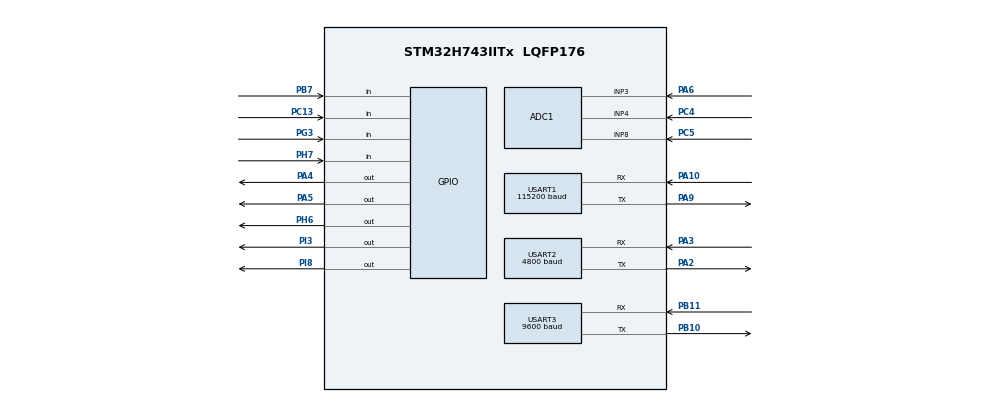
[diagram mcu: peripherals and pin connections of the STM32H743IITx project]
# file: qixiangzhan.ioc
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ADC1.Channel-8\#ChannelRegularConversion=ADC_CHANNEL_8
ADC1.ContinuousConvMode=DISABLE
ADC1.ConversionDataManagement=ADC_CONVERSIONDATA_DR
ADC1.EOCSelection=ADC_EOC_SINGLE_CONV
ADC1.NbrOfConversionFlag=1
ADC1.OffsetNumber-8\#ChannelRegularConversion=ADC_OFFSET_NONE
ADC1.OffsetSignedSaturation-8\#ChannelRegularConversion=DISABLE
ADC1.Overrun=ADC_OVR_DATA_PRESERVED
ADC1.Rank-8\#ChannelRegularConversion=1
ADC1.SamplingTime-8\#ChannelRegularConversion=ADC_SAMPLETIME_64CYCLES_5
ADC1.ScanConvMode=ADC_SCAN_DISABLE
ADC1.master=1
CORTEX_M7.default_mode_Activation=1
Dma.ADC1.0.Direction=DMA_PERIPH_TO_MEMORY
Dma.ADC1.0.EventEnable=DISABLE
Dma.ADC1.0.FIFOMode=DMA_FIFOMODE_DISABLE
Dma.ADC1.0.Instance=DMA1_Stream0
Dma.ADC1.0.MemDataAlignment=DMA_MDATAALIGN_HALFWORD
Dma.ADC1.0.MemInc=DMA_MINC_ENABLE
Dma.ADC1.0.Mode=DMA_CIRCULAR
Dma.ADC1.0.PeriphDataAlignment=DMA_PDATAALIGN_HALFWORD
Dma.ADC1.0.PeriphInc=DMA_PINC_DISABLE
Dma.ADC1.0.Polarity=HAL_DMAMUX_REQ_GEN_RISING
Dma.ADC1.0.Priority=DMA_PRIORITY_HIGH
Dma.ADC1.0.RequestNumber=1
Dma.ADC1.0.SignalID=NONE
Dma.ADC1.0.SyncEnable=DISABLE
Dma.ADC1.0.SyncPolarity=HAL_DMAMUX_SYNC_NO_EVENT
Dma.ADC1.0.SyncRequestNumber=1
Dma.ADC1.0.SyncSignalID=NONE
Dma.Request0=ADC1
Mcu.Family=STM32H7
Mcu.Name=STM32H743IITx
Mcu.Package=LQFP176
NVIC.DMA1_Stream0_IRQn=true\:5\:0\:false\:false\:true\:true\:false\:true
NVIC.PriorityGroup=NVIC_PRIORITYGROUP_4
NVIC.USART1_IRQn=true\:0\:0\:false\:false\:true\:true\:true\:true
NVIC.USART2_IRQn=true\:0\:0\:false\:false\:true\:true\:true\:true
NVIC.USART3_IRQn=true\:0\:0\:false\:false\:true\:true\:true\:true
PA10.Mode=Asynchronous
PA10.Signal=USART1_RX
PA13\ (JTMS/SWDIO).Mode=Serial_Wire
PA13\ (JTMS/SWDIO).Signal=DEBUG_JTMS-SWDIO
PA14\ (JTCK/SWCLK).Mode=Serial_Wire
PA14\ (JTCK/SWCLK).Signal=DEBUG_JTCK-SWCLK
PA2.Mode=Asynchronous
PA2.Signal=USART2_TX
PA3.Mode=Asynchronous
PA3.Signal=USART2_RX
PA4.PinState=GPIO_PIN_SET
PA4.Signal=GPIO_Output
PA5.PinState=GPIO_PIN_SET
PA5.Signal=GPIO_Output
PA6.Signal=ADCx_INP3
PA9.Mode=Asynchronous
PA9.Signal=USART1_TX
PB10.Mode=Asynchronous
PB10.Signal=USART3_TX
PB11.Mode=Asynchronous
PB11.Signal=USART3_RX
PB7.GPIO_Mode=GPIO_MODE_INPUT
PB7.GPIO_PuPd=GPIO_PULLUP
PB7.Signal=GPIO_Input
PC13.GPIO_Mode=GPIO_MODE_INPUT
PC13.GPIO_PuPd=GPIO_PULLUP
PC13.Signal=GPIO_Input
PC4.Signal=ADCx_INP4
PC5.Signal=ADCx_INP8
PD0.Signal=FMC_D2_DA2
PD1.Signal=FMC_D3_DA3
PD10.Signal=FMC_D15_DA15
PD13.Signal=FMC_A18
PD14.Signal=FMC_D0_DA0
PD15.Signal=FMC_D1_DA1
PD4.Signal=FMC_NOE
PD5.Signal=FMC_NWE
PD7.Signal=FMC_NE1
PD8.Signal=FMC_D13_DA13
PD9.Signal=FMC_D14_DA14
PE10.Signal=FMC_D7_DA7
PE11.Signal=FMC_D8_DA8
PE12.Signal=FMC_D9_DA9
PE13.Signal=FMC_D10_DA10
PE14.Signal=FMC_D11_DA11
PE15.Signal=FMC_D12_DA12
PE7.Signal=FMC_D4_DA4
PE8.Signal=FMC_D5_DA5
PE9.Signal=FMC_D6_DA6
PG3.GPIO_Mode=GPIO_MODE_INPUT
PG3.GPIO_PuPd=GPIO_NOPULL
PG3.Signal=GPIO_Input
PH6.GPIO_Mode=GPIO_MODE_OUTPUT_PP
PH6.GPIO_PuPd=GPIO_PULLUP
PH6.PinState=GPIO_PIN_SET
PH6.Signal=GPIO_Output
PH7.GPIO_Mode=GPIO_MODE_INPUT
PH7.GPIO_PuPd=GPIO_PULLUP
PH7.Signal=GPIO_Input
PI3.GPIO_Mode=GPIO_MODE_OUTPUT_OD
PI3.GPIO_PuPd=GPIO_PULLUP
PI3.PinState=GPIO_PIN_SET
PI3.Signal=GPIO_Output
PI8.GPIO_Mode=GPIO_MODE_OUTPUT_PP
PI8.GPIO_PuPd=GPIO_PULLUP
PI8.PinState=GPIO_PIN_SET
PI8.Signal=GPIO_Output
ProjectManager.HeapSize=0x200
ProjectManager.StackSize=0x1000
ProjectManager.TargetToolchain=MDK-ARM V5.32
RCC.ADCFreq_Value=75000000
RCC.APB1Freq_Value=32000000
RCC.APB2Freq_Value=32000000
RCC.APB3Freq_Value=64000000
RCC.APB4Freq_Value=64000000
RCC.CortexFreq_Value=64000000
RCC.D2PPRE1=RCC_APB1_DIV2
RCC.D2PPRE2=RCC_APB2_DIV2
RCC.DIVM2=4
RCC.DIVN2=9
RCC.HCLKFreq_Value=64000000
RCC.PLL2FRACN=3072
RCC.SYSCLKFreq_VALUE=64000000
RCC.USBFreq_Value=129000000
SH.ADCx_INP3.0=ADC1_INP3,IN3-Single-Ended
SH.ADCx_INP4.0=ADC1_INP4,IN4-Single-Ended
SH.ADCx_INP8.0=ADC1_INP8,IN8-Single-Ended
SH.FMC_A18.0=FMC_A18
SH.FMC_D0_DA0.0=FMC_D0
SH.FMC_D10_DA10.0=FMC_D10
SH.FMC_D11_DA11.0=FMC_D11
SH.FMC_D12_DA12.0=FMC_D12
SH.FMC_D13_DA13.0=FMC_D13
SH.FMC_D14_DA14.0=FMC_D14
SH.FMC_D15_DA15.0=FMC_D15
SH.FMC_D1_DA1.0=FMC_D1
SH.FMC_D2_DA2.0=FMC_D2
SH.FMC_D3_DA3.0=FMC_D3
SH.FMC_D4_DA4.0=FMC_D4
SH.FMC_D5_DA5.0=FMC_D5
SH.FMC_D6_DA6.0=FMC_D6
SH.FMC_D7_DA7.0=FMC_D7
SH.FMC_D8_DA8.0=FMC_D8
SH.FMC_D9_DA9.0=FMC_D9
SH.FMC_NOE.0=FMC_NOE
SH.FMC_NWE.0=FMC_NWE
USART1.BaudRate=115200
USART1.VirtualMode-Asynchronous=VM_ASYNC
USART2.BaudRate=4800
USART2.VirtualMode-Asynchronous=VM_ASYNC
USART3.BaudRate=9600
USART3.VirtualMode-Asynchronous=VM_ASYNC
VP_MEMORYMAP_VS_MEMORYMAP.Mode=CurAppReg
board=custom

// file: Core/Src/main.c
/* USER CODE BEGIN Header */
/**
  ******************************************************************************
  * @file           : main.c
  * @brief          : Main program body
  ******************************************************************************
  * @attention
  *
  * Copyright (c) 2026 STMicroelectronics.
  * All rights reserved.
  *
  * This software is licensed under terms that can be found in the LICENSE file
  * in the root directory of this software component.
  * If no LICENSE file comes with this software, it is provided AS-IS.
  *
  ******************************************************************************
  */
/* USER CODE END Header */
#include "main.h"
#include "adc.h"
#include "dma.h"
#include "usart.h"
#include "gpio.h"

/* USER CODE BEGIN Includes */
#include "app_main.h"
#include "usart.h"

/* USER CODE END Includes */

void SystemClock_Config(void);
static void MPU_Config(void);

int main(void)
{

  /* MPU Configuration--------------------------------------------------------*/
  MPU_Config();

  /* MCU Configuration--------------------------------------------------------*/

  /* Reset of all peripherals, Initializes the Flash interface and the Systick. */
  HAL_Init();

  /* Configure the system clock */
  SystemClock_Config();

  /* Initialize all configured peripherals */
  MX_GPIO_Init();
  MX_DMA_Init();
  MX_USART1_UART_Init();
  MX_USART2_UART_Init();
  MX_USART3_UART_Init();
  MX_ADC1_Init();
  /* USER CODE BEGIN 2 */
  App_MainInit();
  /* USER CODE END 2 */

  /* Infinite loop */
  while (1)
  {

    /* USER CODE BEGIN 3 */
    App_MainTask();
  }
  /* USER CODE END 3 */
}

void SystemClock_Config(void)
{
  RCC_OscInitTypeDef RCC_OscInitStruct = {0};
  RCC_ClkInitTypeDef RCC_ClkInitStruct = {0};

  /** Supply configuration update enable
  */
  HAL_PWREx_ConfigSupply(PWR_LDO_SUPPLY);

  /** Configure the main internal regulator output voltage
  */
  __HAL_PWR_VOLTAGESCALING_CONFIG(PWR_REGULATOR_VOLTAGE_SCALE3);

  while(!__HAL_PWR_GET_FLAG(PWR_FLAG_VOSRDY)) {}

  /** Macro to configure the PLL clock source
  */
  __HAL_RCC_PLL_PLLSOURCE_CONFIG(RCC_PLLSOURCE_HSI);

  /** Initializes the RCC Oscillators according to the specified parameters
  * in the RCC_OscInitTypeDef structure.
  */
  RCC_OscInitStruct.OscillatorType = RCC_OSCILLATORTYPE_HSI;
  RCC_OscInitStruct.HSIState = RCC_HSI_DIV1;
  RCC_OscInitStruct.HSICalibrationValue = RCC_HSICALIBRATION_DEFAULT;
  RCC_OscInitStruct.PLL.PLLState = RCC_PLL_NONE;
  if (HAL_RCC_OscConfig(&RCC_OscInitStruct) != HAL_OK)
  {
    Error_Handler();
  }

  /** Initializes the CPU, AHB and APB buses clocks
  */
  RCC_ClkInitStruct.ClockType = RCC_CLOCKTYPE_HCLK|RCC_CLOCKTYPE_SYSCLK
                              |RCC_CLOCKTYPE_PCLK1|RCC_CLOCKTYPE_PCLK2
                              |RCC_CLOCKTYPE_D3PCLK1|RCC_CLOCKTYPE_D1PCLK1;
  RCC_ClkInitStruct.SYSCLKSource = RCC_SYSCLKSOURCE_HSI;
  RCC_ClkInitStruct.SYSCLKDivider = RCC_SYSCLK_DIV1;
  RCC_ClkInitStruct.AHBCLKDivider = RCC_HCLK_DIV1;
  RCC_ClkInitStruct.APB3CLKDivider = RCC_APB3_DIV1;
  RCC_ClkInitStruct.APB1CLKDivider = RCC_APB1_DIV2;
  RCC_ClkInitStruct.APB2CLKDivider = RCC_APB2_DIV2;
  RCC_ClkInitStruct.APB4CLKDivider = RCC_APB4_DIV1;

  if (HAL_RCC_ClockConfig(&RCC_ClkInitStruct, FLASH_LATENCY_1) != HAL_OK)
  {
    Error_Handler();
  }
}

 /* MPU Configuration */

void MPU_Config(void)
{
  MPU_Region_InitTypeDef MPU_InitStruct = {0};

  /* Disables the MPU */
  HAL_MPU_Disable();

  /** Initializes and configures the Region and the memory to be protected
  */
  MPU_InitStruct.Enable = MPU_REGION_ENABLE;
  MPU_InitStruct.Number = MPU_REGION_NUMBER0;
  MPU_InitStruct.BaseAddress = 0x0;
  MPU_InitStruct.Size = MPU_REGION_SIZE_4GB;
  MPU_InitStruct.SubRegionDisable = 0x87;
  MPU_InitStruct.TypeExtField = MPU_TEX_LEVEL0;
  MPU_InitStruct.AccessPermission = MPU_REGION_NO_ACCESS;
  MPU_InitStruct.DisableExec = MPU_INSTRUCTION_ACCESS_DISABLE;
  MPU_InitStruct.IsShareable = MPU_ACCESS_SHAREABLE;
  MPU_InitStruct.IsCacheable = MPU_ACCESS_NOT_CACHEABLE;
  MPU_InitStruct.IsBufferable = MPU_ACCESS_NOT_BUFFERABLE;

  HAL_MPU_ConfigRegion(&MPU_InitStruct);
  /* Enables the MPU */
  HAL_MPU_Enable(MPU_PRIVILEGED_DEFAULT);

}

void Error_Handler(void)
{
  __disable_irq();
  while (1)
  {
  }
}
